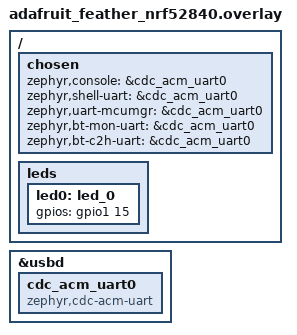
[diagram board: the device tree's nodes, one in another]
/*
 * Copyright (c) 2024 Jacob Winther
 *
 * SPDX-License-Identifier: Apache-2.0
 */

/dts-v1/;
#include "nrf52840_partition_uf2_sdv6.dtsi"

/ {
	chosen {
		zephyr,console = &cdc_acm_uart0;
		zephyr,shell-uart = &cdc_acm_uart0;
		zephyr,uart-mcumgr = &cdc_acm_uart0;
		zephyr,bt-mon-uart = &cdc_acm_uart0;
		zephyr,bt-c2h-uart = &cdc_acm_uart0;
	};

	leds {
		led0: led_0 {
			gpios = <&gpio1 15 0>;
		};
	};
};

zephyr_udc0: &usbd {
	cdc_acm_uart0: cdc_acm_uart0 {
		compatible = "zephyr,cdc-acm-uart";
	};
};
